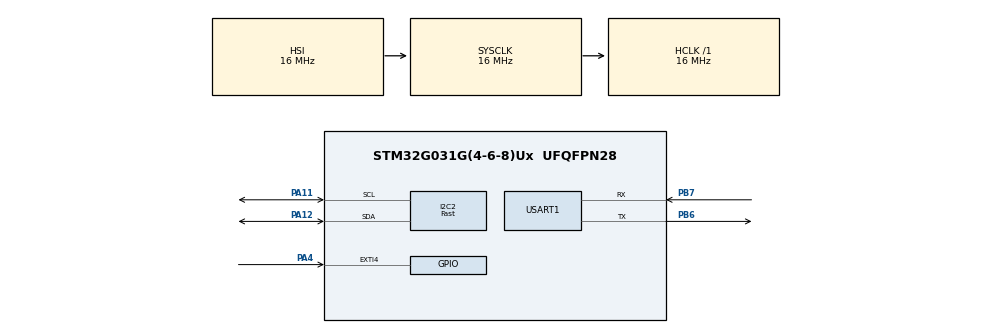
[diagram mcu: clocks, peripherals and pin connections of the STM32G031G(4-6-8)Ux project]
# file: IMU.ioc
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I2C2.I2C_Fall_Time=100
I2C2.I2C_Rise_Time=100
I2C2.I2C_Speed_Mode=I2C_Fast
I2C2.OwnAddress=0x7e
I2C2.Speed=250
I2C2.Timing=0x0030062F
Mcu.Family=STM32G0
Mcu.Name=STM32G031G(4-6-8)Ux
Mcu.Package=UFQFPN28
PA11\ [PA9].Mode=I2C
PA11\ [PA9].Signal=I2C2_SCL
PA12\ [PA10].Mode=I2C
PA12\ [PA10].Signal=I2C2_SDA
PA13.Mode=Serial_Wire
PA13.Signal=SYS_SWDIO
PA14-BOOT0.Mode=Serial_Wire
PA14-BOOT0.Signal=SYS_SWCLK
PA4.GPIO_ModeDefaultEXTI=GPIO_MODE_IT_FALLING
PA4.Signal=GPXTI4
PB6.Mode=Asynchronous
PB6.Signal=USART1_TX
PB7.Mode=Asynchronous
PB7.Signal=USART1_RX
ProjectManager.HeapSize=0x200
ProjectManager.StackSize=0x400
ProjectManager.TargetToolchain=MDK-ARM V5
RCC.AHBFreq_Value=16000000
RCC.CortexFreq_Value=16000000
RCC.EXTERNAL_CLOCK_VALUE=12288000
RCC.HCLKFreq_Value=16000000
RCC.HSE_VALUE=8000000
RCC.HSI_VALUE=16000000
RCC.LSE_VALUE=32768
RCC.SYSCLKFreq_VALUE=16000000
RCC.VCOOutputFreq_Value=128000000
USART1.VirtualMode-Asynchronous=VM_ASYNC
board=custom

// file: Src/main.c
/* USER CODE BEGIN Header */
/**
  ******************************************************************************
  * @file           : main.c
  * @brief          : Main program body
  ******************************************************************************
  * @attention
  *
  * <h2><center>&copy; Copyright (c) 2020 STMicroelectronics.
  * All rights reserved.</center></h2>
  *
  * This software component is licensed by ST under BSD 3-Clause license,
  * the "License"; You may not use this file except in compliance with the
  * License. You may obtain a copy of the License at:
  *                        opensource.org/licenses/BSD-3-Clause
  *
  ******************************************************************************
  */
/* USER CODE END Header */

/* USER CODE BEGIN Includes */
#include "ICM20948.h"
#include "sensor.h"
/* USER CODE END Includes */

/* USER CODE BEGIN PTD */
extern mag_acc_gyro_stru mag_acc_gyro;
/* USER CODE END PTD */

I2C_HandleTypeDef hi2c2;

UART_HandleTypeDef huart1;

void SystemClock_Config(void);
static void MX_GPIO_Init(void);
static void MX_I2C2_Init(void);
static void MX_USART1_UART_Init(void);

int main(void)
{

  /* MCU Configuration--------------------------------------------------------*/

  /* Reset of all peripherals, Initializes the Flash interface and the Systick. */
  HAL_Init();

  /* Configure the system clock */
  SystemClock_Config();

  /* Initialize all configured peripherals */
  MX_GPIO_Init();
  MX_I2C2_Init();
  MX_USART1_UART_Init();
  /* USER CODE BEGIN 2 */
  Chip_Init();

  /* USER CODE END 2 */

  /* Infinite loop */
  while (1)
  {

    /* USER CODE BEGIN 3 */
		ICM_Process();
		Angle_Calcu(mag_acc_gyro.accel_data[0],mag_acc_gyro.gyro_data[1]);
  }
  /* USER CODE END 3 */
}

void SystemClock_Config(void)
{
  RCC_OscInitTypeDef RCC_OscInitStruct = {0};
  RCC_ClkInitTypeDef RCC_ClkInitStruct = {0};
  RCC_PeriphCLKInitTypeDef PeriphClkInit = {0};

  /** Configure the main internal regulator output voltage
  */
  HAL_PWREx_ControlVoltageScaling(PWR_REGULATOR_VOLTAGE_SCALE1);
  /** Initializes the CPU, AHB and APB busses clocks
  */
  RCC_OscInitStruct.OscillatorType = RCC_OSCILLATORTYPE_HSI;
  RCC_OscInitStruct.HSIState = RCC_HSI_ON;
  RCC_OscInitStruct.HSIDiv = RCC_HSI_DIV1;
  RCC_OscInitStruct.HSICalibrationValue = RCC_HSICALIBRATION_DEFAULT;
  RCC_OscInitStruct.PLL.PLLState = RCC_PLL_NONE;
  if (HAL_RCC_OscConfig(&RCC_OscInitStruct) != HAL_OK)
  {
    Error_Handler();
  }
  /** Initializes the CPU, AHB and APB busses clocks
  */
  RCC_ClkInitStruct.ClockType = RCC_CLOCKTYPE_HCLK|RCC_CLOCKTYPE_SYSCLK
                              |RCC_CLOCKTYPE_PCLK1;
  RCC_ClkInitStruct.SYSCLKSource = RCC_SYSCLKSOURCE_HSI;
  RCC_ClkInitStruct.AHBCLKDivider = RCC_SYSCLK_DIV1;
  RCC_ClkInitStruct.APB1CLKDivider = RCC_HCLK_DIV1;

  if (HAL_RCC_ClockConfig(&RCC_ClkInitStruct, FLASH_LATENCY_0) != HAL_OK)
  {
    Error_Handler();
  }
  /** Initializes the peripherals clocks
  */
  PeriphClkInit.PeriphClockSelection = RCC_PERIPHCLK_USART1;
  PeriphClkInit.Usart1ClockSelection = RCC_USART1CLKSOURCE_PCLK1;
  if (HAL_RCCEx_PeriphCLKConfig(&PeriphClkInit) != HAL_OK)
  {
    Error_Handler();
  }
}

static void MX_I2C2_Init(void)
{

  hi2c2.Instance = I2C2;
  hi2c2.Init.Timing = 0x0030062F;
  hi2c2.Init.OwnAddress1 = 252;
  hi2c2.Init.AddressingMode = I2C_ADDRESSINGMODE_7BIT;
  hi2c2.Init.DualAddressMode = I2C_DUALADDRESS_DISABLE;
  hi2c2.Init.OwnAddress2 = 0;
  hi2c2.Init.OwnAddress2Masks = I2C_OA2_NOMASK;
  hi2c2.Init.GeneralCallMode = I2C_GENERALCALL_DISABLE;
  hi2c2.Init.NoStretchMode = I2C_NOSTRETCH_DISABLE;
  if (HAL_I2C_Init(&hi2c2) != HAL_OK)
  {
    Error_Handler();
  }
  /** Configure Analogue filter
  */
  if (HAL_I2CEx_ConfigAnalogFilter(&hi2c2, I2C_ANALOGFILTER_ENABLE) != HAL_OK)
  {
    Error_Handler();
  }
  /** Configure Digital filter
  */
  if (HAL_I2CEx_ConfigDigitalFilter(&hi2c2, 0) != HAL_OK)
  {
    Error_Handler();
  }

}

static void MX_USART1_UART_Init(void)
{

  huart1.Instance = USART1;
  huart1.Init.BaudRate = 115200;
  huart1.Init.WordLength = UART_WORDLENGTH_7B;
  huart1.Init.StopBits = UART_STOPBITS_1;
  huart1.Init.Parity = UART_PARITY_NONE;
  huart1.Init.Mode = UART_MODE_TX_RX;
  huart1.Init.HwFlowCtl = UART_HWCONTROL_NONE;
  huart1.Init.OverSampling = UART_OVERSAMPLING_16;
  huart1.Init.OneBitSampling = UART_ONE_BIT_SAMPLE_DISABLE;
  huart1.Init.ClockPrescaler = UART_PRESCALER_DIV1;
  huart1.AdvancedInit.AdvFeatureInit = UART_ADVFEATURE_NO_INIT;
  if (HAL_UART_Init(&huart1) != HAL_OK)
  {
    Error_Handler();
  }
  if (HAL_UARTEx_SetTxFifoThreshold(&huart1, UART_TXFIFO_THRESHOLD_1_8) != HAL_OK)
  {
    Error_Handler();
  }
  if (HAL_UARTEx_SetRxFifoThreshold(&huart1, UART_RXFIFO_THRESHOLD_1_8) != HAL_OK)
  {
    Error_Handler();
  }
  if (HAL_UARTEx_DisableFifoMode(&huart1) != HAL_OK)
  {
    Error_Handler();
  }

}

static void MX_GPIO_Init(void)
{
  GPIO_InitTypeDef GPIO_InitStruct = {0};

  /* GPIO Ports Clock Enable */
  __HAL_RCC_GPIOA_CLK_ENABLE();
  __HAL_RCC_GPIOB_CLK_ENABLE();

  /*Configure GPIO pin : PA4 */
  GPIO_InitStruct.Pin = GPIO_PIN_4;
  GPIO_InitStruct.Mode = GPIO_MODE_IT_FALLING;
  GPIO_InitStruct.Pull = GPIO_NOPULL;
  HAL_GPIO_Init(GPIOA, &GPIO_InitStruct);

}

void Error_Handler(void)
{
}

/************************ (C) COPYRIGHT STMicroelectronics *****END OF FILE****/
